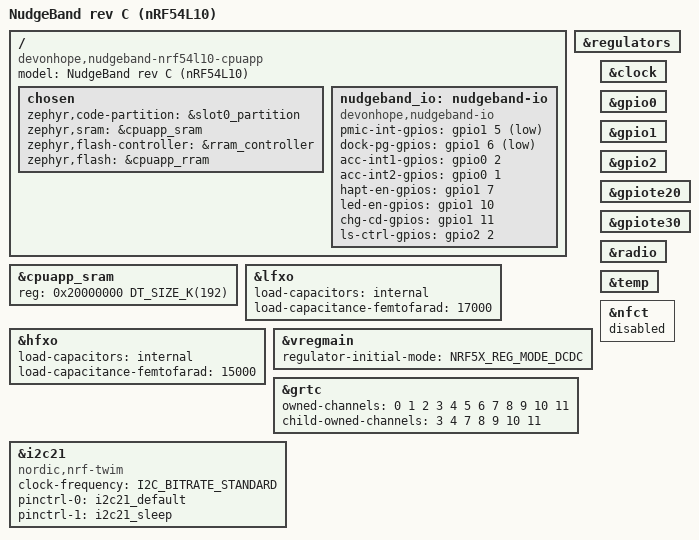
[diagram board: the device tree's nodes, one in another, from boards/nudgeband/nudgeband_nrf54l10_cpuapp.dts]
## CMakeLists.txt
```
# NudgeBand firmware (Zephyr / nRF Connect SDK application)
# SPDX-License-Identifier: MIT
cmake_minimum_required(VERSION 3.20.0)

# The NudgeBand board definition lives in this repo (boards/nudgeband).
list(APPEND BOARD_ROOT ${CMAKE_CURRENT_SOURCE_DIR})
list(APPEND DTS_ROOT ${CMAKE_CURRENT_SOURCE_DIR})

find_package(Zephyr REQUIRED HINTS $ENV{ZEPHYR_BASE})
project(nudgeband)

target_sources(app PRIVATE
	src/main.c
	src/board_io.c
	src/accel.c
	src/haptics.c
	src/led.c
	src/pmic.c
	src/ble.c
	# hardware-independent, also built by tests/host
	src/activity.c
	src/smartwake.c
	src/alarm.c
	src/protocol.c
)
```

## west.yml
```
# West manifest for building the firmware with upstream Zephyr (also what CI uses).
#   west init -l <repo checkout> --mf firmware/west.yml && west update
#   (run from the folder that holds the checkout; that folder becomes the west workspace)
# Building with nRF Connect SDK instead works too: see firmware/README.md.
manifest:
  remotes:
    - name: zephyrproject-rtos
      url-base: https://github.com/zephyrproject-rtos
  projects:
    - name: zephyr
      remote: zephyrproject-rtos
      revision: v4.2.0
      import:
        name-allowlist:
          - cmsis_6
          - hal_nordic
          - mbedtls
          - segger
```

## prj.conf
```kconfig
# NudgeBand firmware configuration
CONFIG_GPIO=y
CONFIG_I2C=y

# Logs over SEGGER RTT through the dock's SWD pins (no UART on the band)
CONFIG_LOG=y
CONFIG_USE_SEGGER_RTT=y
CONFIG_LOG_BACKEND_RTT=y
CONFIG_LOG_BACKEND_UART=n
CONFIG_CONSOLE=y
CONFIG_RTT_CONSOLE=y
CONFIG_UART_CONSOLE=n

# Bluetooth peripheral (docs/ble-protocol.md)
CONFIG_BT=y
CONFIG_BT_PERIPHERAL=y
CONFIG_BT_DEVICE_NAME="NudgeBand"
CONFIG_BT_DEVICE_NAME_DYNAMIC=y
CONFIG_BT_SMP=y
CONFIG_BT_BONDABLE=y
CONFIG_BT_MAX_PAIRED=1
CONFIG_BT_MAX_CONN=1
CONFIG_BT_GATT_DYNAMIC_DB=n
CONFIG_BT_BAS=y
CONFIG_BT_DIS=y
CONFIG_BT_DIS_MODEL="NudgeBand"
CONFIG_BT_DIS_MANUF="NudgeBand project"
CONFIG_BT_DIS_HW_REV=y
CONFIG_BT_DIS_HW_REV_STR="rev C"
CONFIG_BT_DIS_FW_REV=y
CONFIG_BT_DIS_FW_REV_STR="0.1"

# Bonds survive a reset (settings in RRAM)
CONFIG_FLASH=y
CONFIG_FLASH_MAP=y
CONFIG_ZMS=y
CONFIG_SETTINGS=y
CONFIG_BT_SETTINGS=y

CONFIG_MAIN_STACK_SIZE=2048
```

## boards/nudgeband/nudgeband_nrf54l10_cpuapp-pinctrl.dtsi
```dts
/* SPDX-License-Identifier: MIT */

&pinctrl {
	/* External pull-ups R203/R204 to the 2.0 V rail. P1.04 and P1.08 are clock-capable pins. */
	i2c21_default: i2c21_default {
		group1 {
			psels = <NRF_PSEL(TWIM_SCL, 1, 4)>,
				<NRF_PSEL(TWIM_SDA, 1, 8)>;
		};
	};

	i2c21_sleep: i2c21_sleep {
		group1 {
			psels = <NRF_PSEL(TWIM_SCL, 1, 4)>,
				<NRF_PSEL(TWIM_SDA, 1, 8)>;
			low-power-enable;
		};
	};
};
```

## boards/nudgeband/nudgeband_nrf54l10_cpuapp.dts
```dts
/*
 * NudgeBand rev C (hardware/band/rev-c/pcb). Pin map and part notes: that folder's README.md.
 *
 * SPDX-License-Identifier: MIT
 */

/dts-v1/;

#include <nordic/nrf54l10_cpuapp.dtsi>
#include "nudgeband_nrf54l10_cpuapp-pinctrl.dtsi"

/ {
	compatible = "devonhope,nudgeband-nrf54l10-cpuapp";
	model = "NudgeBand rev C (nRF54L10)";

	chosen {
		zephyr,code-partition = &slot0_partition;
		zephyr,sram = &cpuapp_sram;
		zephyr,flash-controller = &rram_controller;
		zephyr,flash = &cpuapp_rram;
	};

	/* Board signals the application drives itself (src/board_io.c). Pin map: band rev C README. */
	nudgeband_io: nudgeband-io {
		compatible = "devonhope,nudgeband-io";
		/* BQ25125 /INT and /PG are open drain with no external pull-ups: use the internal ones. */
		pmic-int-gpios = <&gpio1 5 (GPIO_ACTIVE_LOW | GPIO_PULL_UP)>;
		dock-pg-gpios = <&gpio1 6 (GPIO_ACTIVE_LOW | GPIO_PULL_UP)>; /* low while docked */
		acc-int1-gpios = <&gpio0 2 GPIO_ACTIVE_HIGH>;  /* LIS2DW12 INT1: FIFO watermark */
		acc-int2-gpios = <&gpio0 1 GPIO_ACTIVE_HIGH>;  /* LIS2DW12 INT2: double tap */
		hapt-en-gpios = <&gpio1 7 GPIO_ACTIVE_HIGH>;   /* DRV2605L EN */
		led-en-gpios = <&gpio1 10 GPIO_ACTIVE_HIGH>;   /* IS31FL3193 SDB (R211 pulls low) */
		chg-cd-gpios = <&gpio1 11 GPIO_ACTIVE_HIGH>;   /* BQ25125 /CD: high = I2C, low = Hi-Z */
		ls-ctrl-gpios = <&gpio2 2 GPIO_ACTIVE_HIGH>;   /* BQ25125 LSCTRL: LED supply */
	};

};

&cpuapp_sram {
	status = "okay";
	reg = <0x20000000 DT_SIZE_K(192)>;
	ranges = <0x0 0x20000000 DT_SIZE_K(192)>;
};

/*
 * Crystals use the chip's internal load capacitors (no external caps on the board).
 * X1 32.768 kHz CL 9 pF, X2 32 MHz CL 8 pF: same crystals' CL as the nRF54L15 DK, so its values are
 * the starting point. Check the INTCAP formula against our layout's parasitics (TODO.md, 1.3).
 */
&lfxo {
	load-capacitors = "internal";
	load-capacitance-femtofarad = <17000>;
};

&hfxo {
	load-capacitors = "internal";
	load-capacitance-femtofarad = <15000>;
};

&regulators {
	status = "okay";
};

/* L1 4.7 uH is fitted: run the main regulator as DC/DC. */
&vregmain {
	status = "okay";
	regulator-initial-mode = <NRF5X_REG_MODE_DCDC>;
};

&grtc {
	owned-channels = <0 1 2 3 4 5 6 7 8 9 10 11>;
	child-owned-channels = <3 4 7 8 9 10 11>;
	status = "okay";
};

&clock {
	status = "okay";
};

&gpio0 {
	status = "okay";
};

&gpio1 {
	status = "okay";
};

&gpio2 {
	status = "okay";
};

&gpiote20 {
	status = "okay";
};

&gpiote30 {
	status = "okay";
};

&radio {
	status = "okay";
};

&temp {
	status = "okay";
};

/* NFC pins (P1.02/P1.03) are unused. */
&nfct {
	status = "disabled";
};

&i2c21 {
	status = "okay";
	compatible = "nordic,nrf-twim";
	clock-frequency = <I2C_BITRATE_STANDARD>;
	pinctrl-0 = <&i2c21_default>;
	pinctrl-1 = <&i2c21_sleep>;
	pinctrl-names = "default", "sleep";

	/* Motion sensor: INT1 = FIFO watermark, INT2 = double tap (dismiss) */
	/*
	 * All four parts are driven by small register-level modules in src/ (fixed addresses there):
	 * LIS2DW12 0x19, DRV2605L 0x5A, IS31FL3193 0x68, BQ25125 0x6A. Zephyr's own LIS2DW12 and
	 * DRV2605 drivers can replace two of them later (TODO.md, 2.x).
	 */
};

/* Default 1 MB RRAM partitions (MCUboot slots etc.) */
#include <nordic/nrf54l10_partition.dtsi>
```

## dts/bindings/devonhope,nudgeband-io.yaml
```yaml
# SPDX-License-Identifier: MIT
description: NudgeBand board signals driven directly by the application

compatible: "devonhope,nudgeband-io"

properties:
  pmic-int-gpios:
    type: phandle-array
    required: true
    description: BQ25125 /INT
  dock-pg-gpios:
    type: phandle-array
    required: true
    description: BQ25125 /PG, active while the dock supplies VIN
  acc-int1-gpios:
    type: phandle-array
    required: true
  acc-int2-gpios:
    type: phandle-array
    required: true
  hapt-en-gpios:
    type: phandle-array
    required: true
  led-en-gpios:
    type: phandle-array
    required: true
  chg-cd-gpios:
    type: phandle-array
    required: true
  ls-ctrl-gpios:
    type: phandle-array
    required: true
```

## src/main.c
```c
/*
 * NudgeBand firmware: track movement all night, wake the wearer gently in light sleep inside the
 * window before the alarm. Status of every part: ../TODO.md.
 */
#include <zephyr/kernel.h>
#include <zephyr/logging/log.h>

#include "accel.h"
#include "activity.h"
#include "alarm.h"
#include "band.h"
#include "ble.h"
#include "board_io.h"
#include "haptics.h"
#include "led.h"
#include "pmic.h"
#include "smartwake.h"

LOG_MODULE_REGISTER(main, LOG_LEVEL_INF);

#define EPOCH_S 30

static K_MUTEX_DEFINE(lock);
static K_SEM_DEFINE(fifo_ready, 0, 1);

/* Time: UTC at the moment the phone set it, plus uptime since then. */
static uint32_t utc_at_set;
static int64_t uptime_at_set_ms;
static int16_t tz_offset_min;
static bool time_set;

static struct nb_alarm_cfg alarm_cfg;
static uint32_t next_alarm_utc;
static enum nb_state state = NB_STATE_IDLE;
static uint8_t repeats_left;
static enum nb_wake_reason last_wake_reason;
static uint32_t last_wake_utc;

static struct smartwake sw;
static struct activity_acc acc;

static void repeat_fn(struct k_work *w);
static K_WORK_DELAYABLE_DEFINE(repeat_work, repeat_fn);

uint32_t band_now_utc(void)
{
	if (!time_set) {
		return 0;
	}
	return utc_at_set + (uint32_t)((k_uptime_get() - uptime_at_set_ms) / 1000);
}

static void rearm_locked(void)
{
	struct smartwake_cfg cfg;
	uint32_t now = band_now_utc();

	next_alarm_utc = now ? alarm_next_utc(&alarm_cfg, now, tz_offset_min) : 0;
	if (!next_alarm_utc) {
		smartwake_disarm(&sw);
		state = NB_STATE_IDLE;
		return;
	}
	smartwake_default_cfg(&cfg);
	cfg.epoch_s = EPOCH_S;
	cfg.window_s = (alarm_cfg.flags & NB_ALARM_FLAG_SMARTWAKE) ? alarm_cfg.window_min * 60u : 0;
	smartwake_arm(&sw, &cfg, next_alarm_utc);
	state = NB_STATE_TRACKING;
	LOG_INF("next alarm at %u (UTC), window %u min", next_alarm_utc, cfg.window_s / 60);
}

void band_set_time(const struct nb_time *t)
{
	k_mutex_lock(&lock, K_FOREVER);
	utc_at_set = t->utc;
	uptime_at_set_ms = k_uptime_get();
	tz_offset_min = t->tz_offset_min;
	time_set = true;
	if (state == NB_STATE_IDLE || state == NB_STATE_TRACKING) {
		rearm_locked();
	}
	k_mutex_unlock(&lock);
	ble_status_changed();
}

void band_get_time(struct nb_time *t)
{
	t->utc = band_now_utc();
	t->tz_offset_min = tz_offset_min;
	t->reserved = 0;
}

void band_get_alarm(struct nb_alarm_cfg *cfg)
{
	k_mutex_lock(&lock, K_FOREVER);
	*cfg = alarm_cfg;
	k_mutex_unlock(&lock);
}

void band_set_alarm(const struct nb_alarm_cfg *cfg)
{
	k_mutex_lock(&lock, K_FOREVER);
	alarm_cfg = *cfg;
	/* TODO(TODO.md 3.5): keep the alarm in flash (settings) so a reset doesn't lose it. */
	if (state != NB_STATE_WAKING && state != NB_STATE_WAIT_REPEAT) {
		rearm_locked();
	}
	k_mutex_unlock(&lock);
	ble_status_changed();
}

void band_get_status(struct nb_status *st)
{
	k_mutex_lock(&lock, K_FOREVER);
	st->version = NB_STATUS_VERSION;
	st->state = state;
	st->battery_pct = pmic_battery_pct();
	st->flags = (pmic_docked() ? NB_FLAG_DOCKED : 0) | (time_set ? NB_FLAG_TIME_SET : 0) |
		    (next_alarm_utc ? NB_FLAG_ALARM_ARMED : 0) | (sw.n ? NB_FLAG_LOG_HAS_DATA : 0);
	/* TODO(TODO.md 2.1): NB_FLAG_CHARGING from the BQ25125 status register. */
	st->next_alarm_utc = next_alarm_utc;
	st->fw_major = FW_MAJOR;
	st->fw_minor = FW_MINOR;
	st->last_wake_reason = last_wake_reason;
	st->reserved = 0;
	st->last_wake_utc = last_wake_utc;
	st->stored_epochs = sw.n; /* RAM only for now (TODO.md 3.4) */
	k_mutex_unlock(&lock);
}

static void buzz_locked(void)
{
	(void)haptics_start(alarm_cfg.intensity, alarm_cfg.pattern, alarm_cfg.ramp_s,
			    alarm_cfg.buzz_s);
	state = NB_STATE_WAKING;
	/* After the buzz, wait repeat_min, then buzz again (until dismissed or out of repeats). */
	k_work_reschedule(&repeat_work, K_SECONDS(alarm_cfg.buzz_s));
}

static void repeat_fn(struct k_work *w)
{
	ARG_UNUSED(w);
	k_mutex_lock(&lock, K_FOREVER);
	if (state == NB_STATE_WAKING) {
		if (repeats_left == 0 || alarm_cfg.repeat_min == 0) {
			rearm_locked(); /* done: on to the next alarm */
		} else {
			repeats_left--;
			state = NB_STATE_WAIT_REPEAT;
			k_work_reschedule(&repeat_work, K_MINUTES(alarm_cfg.repeat_min));
		}
	} else if (state == NB_STATE_WAIT_REPEAT) {
		buzz_locked();
	}
	k_mutex_unlock(&lock);
	ble_status_changed();
}

static void wake_locked(enum nb_wake_reason why)
{
	last_wake_reason = why;
	last_wake_utc = band_now_utc();
	repeats_left = alarm_cfg.max_repeats;
	smartwake_disarm(&sw);
	LOG_INF("wake: reason %d", why);
	buzz_locked();
}

enum nb_cp_result band_test_buzz(uint8_t intensity_pct, uint8_t seconds)
{
	if (intensity_pct > 100 || seconds < 1 || seconds > 10) {
		return NB_CP_INVALID;
	}
	if (state == NB_STATE_WAKING) {
		return NB_CP_BUSY;
	}
	return haptics_start((uint8_t)(intensity_pct * 255u / 100u), 0, 1, seconds) ? NB_CP_BUSY
										     : NB_CP_OK;
}

void band_stop_buzz(void)
{
	haptics_stop();
}

void band_dismiss(void)
{
	k_mutex_lock(&lock, K_FOREVER);
	haptics_stop();
	k_work_cancel_delayable(&repeat_work);
	if (state == NB_STATE_WAKING || state == NB_STATE_WAIT_REPEAT ||
	    state == NB_STATE_IN_WINDOW) {
		/* TODO(TODO.md 3.3): dismissing during the window should skip today's alarm only. */
		rearm_locked();
	}
	k_mutex_unlock(&lock);
	ble_status_changed();
}

void band_identify(void)
{
	/* TODO(TODO.md 2.4): blink twice from a work item instead of a fixed on-time. */
	(void)led_set(0, 0, 64);
	k_msleep(300);
	(void)led_set(0, 0, 0);
}

/* Called once per epoch with that epoch's activity. */
static void end_of_epoch(uint16_t activity)
{
	enum smartwake_result r;
	uint32_t now;
	bool changed = false;

	k_mutex_lock(&lock, K_FOREVER);
	now = band_now_utc();
	r = now ? smartwake_feed(&sw, now, activity) : SMARTWAKE_NONE;
	if (state == NB_STATE_TRACKING && sw.armed && now + sw.cfg.window_s >= sw.alarm_s) {
		state = NB_STATE_IN_WINDOW;
		changed = true;
	}
	if (r == SMARTWAKE_LIGHT_SLEEP) {
		wake_locked(NB_WAKE_LIGHT_SLEEP);
		changed = true;
	} else if (r == SMARTWAKE_DEADLINE) {
		wake_locked((alarm_cfg.flags & NB_ALARM_FLAG_SMARTWAKE) ? NB_WAKE_DEADLINE
									 : NB_WAKE_EXACT);
		changed = true;
	}
	k_mutex_unlock(&lock);
	if (changed) {
		ble_status_changed();
	}
}

static struct gpio_callback acc_cb;

static void acc_int1_isr(const struct device *dev, struct gpio_callback *cb, uint32_t pins)
{
	k_sem_give(&fifo_ready);
}

int main(void)
{
	static struct accel_sample batch[32];
	int64_t epoch_end_ms;
	int err;

	LOG_INF("NudgeBand firmware %d.%d", FW_MAJOR, FW_MINOR);

	nb_alarm_cfg_default(&alarm_cfg);
	err = board_io_init();
	if (err) {
		LOG_ERR("board_io_init failed (%d)", err);
		return 0;
	}
	(void)pmic_init();
	(void)led_init();
	(void)haptics_init();
	err = accel_init();
	(void)ble_init();

	if (err == 0) {
		gpio_pin_interrupt_configure_dt(&io_acc_int1, GPIO_INT_EDGE_TO_ACTIVE);
		gpio_init_callback(&acc_cb, acc_int1_isr, BIT(io_acc_int1.pin));
		gpio_add_callback_dt(&io_acc_int1, &acc_cb);
		activity_reset(&acc);
		(void)accel_start();
	}

	epoch_end_ms = k_uptime_get() + EPOCH_S * 1000;
	for (;;) {
		/* The FIFO interrupt normally wakes us every 2 s; the timeout covers a missed one. */
		(void)k_sem_take(&fifo_ready, K_SECONDS(3));

		int n = accel_read_fifo(batch, ARRAY_SIZE(batch));

		if (n > 0) {
			activity_add(&acc, batch, (uint32_t)n);
		}
		/* TODO(TODO.md 3.1): mark epochs as "no data" (0xFFFF) while docked or off the wrist. */
		while (k_uptime_get() >= epoch_end_ms) {
			end_of_epoch(activity_end_epoch(&acc));
			epoch_end_ms += EPOCH_S * 1000;
		}
	}
	return 0;
}
```

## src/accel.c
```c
/*
 * LIS2DW12 register-level driver. Register map: ST DS12086.
 * Low-power mode 1 (12-bit), 12.5 Hz, +/-2 g, FIFO in continuous mode with a watermark on INT1.
 */
#include "accel.h"

#include <zephyr/logging/log.h>
#include <zephyr/sys/byteorder.h>

#include "board_io.h"

LOG_MODULE_REGISTER(accel, LOG_LEVEL_INF);

#define ADDR 0x19

#define REG_WHO_AM_I    0x0F
#define WHO_AM_I_VALUE  0x44
#define REG_CTRL1       0x20
#define REG_CTRL2       0x21
#define REG_CTRL4_INT1  0x23
#define REG_CTRL6       0x25
#define REG_OUT_X_L     0x28
#define REG_FIFO_CTRL   0x2E
#define REG_FIFO_SAMPLES 0x2F

#define CTRL1_ODR_12HZ5    (0x2 << 4)
#define CTRL1_ODR_OFF      (0x0 << 4)
#define CTRL1_LP_MODE1     0x00 /* MODE = low power, LP_MODE = 1 (12-bit) */
#define CTRL2_SOFT_RESET   BIT(6)
#define CTRL2_BDU          BIT(3)
#define CTRL2_IF_ADD_INC   BIT(2)
#define CTRL4_INT1_FTH     BIT(1)
#define CTRL6_FS_2G        (0x0 << 4)
#define FIFO_MODE_BYPASS   (0x0 << 5)
#define FIFO_MODE_CONT     (0x6 << 5)
#define FIFO_SAMPLES_MASK  0x3F

static int wr(uint8_t reg, uint8_t val)
{
	return i2c_reg_write_byte(i2c_bus, ADDR, reg, val);
}

int accel_init(void)
{
	uint8_t id;
	int err = i2c_reg_read_byte(i2c_bus, ADDR, REG_WHO_AM_I, &id);

	if (err) {
		LOG_ERR("no answer at 0x%02x (%d)", ADDR, err);
		return err;
	}
	if (id != WHO_AM_I_VALUE) {
		LOG_ERR("WHO_AM_I 0x%02x, expected 0x%02x", id, WHO_AM_I_VALUE);
		return -ENODEV;
	}
	err = wr(REG_CTRL2, CTRL2_SOFT_RESET);
	k_msleep(5);
	err = err ?: wr(REG_CTRL2, CTRL2_BDU | CTRL2_IF_ADD_INC);
	err = err ?: wr(REG_CTRL6, CTRL6_FS_2G);
	err = err ?: wr(REG_CTRL4_INT1, CTRL4_INT1_FTH);
	return err;
}

int accel_start(void)
{
	int err = wr(REG_FIFO_CTRL, FIFO_MODE_BYPASS); /* clears the FIFO */

	err = err ?: wr(REG_FIFO_CTRL, FIFO_MODE_CONT | ACCEL_FIFO_WTM);
	err = err ?: wr(REG_CTRL1, CTRL1_ODR_12HZ5 | CTRL1_LP_MODE1);
	return err;
}

int accel_stop(void)
{
	return wr(REG_CTRL1, CTRL1_ODR_OFF);
}

int accel_read_fifo(struct accel_sample *out, int max)
{
	uint8_t level;
	int n;
	int err = i2c_reg_read_byte(i2c_bus, ADDR, REG_FIFO_SAMPLES, &level);

	if (err) {
		return err;
	}
	n = MIN((int)(level & FIFO_SAMPLES_MASK), max);
	for (int i = 0; i < n; i++) {
		uint8_t raw[6];

		err = i2c_burst_read(i2c_bus, ADDR, REG_OUT_X_L, raw, sizeof(raw));
		if (err) {
			return err;
		}
		/* 12-bit, left-aligned; at +/-2 g one LSB of the 12-bit value is 0.976 mg */
		out[i].x = (int16_t)(((int32_t)(int16_t)sys_get_le16(&raw[0]) >> 4) * 976 / 1000);
		out[i].y = (int16_t)(((int32_t)(int16_t)sys_get_le16(&raw[2]) >> 4) * 976 / 1000);
		out[i].z = (int16_t)(((int32_t)(int16_t)sys_get_le16(&raw[4]) >> 4) * 976 / 1000);
	}
	return n;
}
```

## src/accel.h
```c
/* LIS2DW12 motion sensor: low-power sampling into its FIFO, read in batches. */
#ifndef NUDGEBAND_ACCEL_H
#define NUDGEBAND_ACCEL_H

#include <stdint.h>

#include "activity.h"

#define ACCEL_ODR_HZ   12.5
#define ACCEL_FIFO_WTM 25 /* samples per batch: one wake every 2 s */

int accel_init(void);

/* Start sampling; INT1 fires each time ACCEL_FIFO_WTM samples are waiting. */
int accel_start(void);
int accel_stop(void);

/* Read every sample in the FIFO (up to max), in mg. Returns the count or a negative error. */
int accel_read_fifo(struct accel_sample *out, int max);

#endif
```

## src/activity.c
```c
#include "activity.h"

static uint32_t absdiff(int16_t a, int16_t b)
{
	int32_t d = (int32_t)a - (int32_t)b;

	return (uint32_t)(d < 0 ? -d : d);
}

void activity_reset(struct activity_acc *acc)
{
	acc->have_prev = false;
	acc->sum = 0;
}

void activity_add(struct activity_acc *acc, const struct accel_sample *s, uint32_t n)
{
	for (uint32_t i = 0; i < n; i++) {
		if (acc->have_prev) {
			uint32_t d = absdiff(s[i].x, acc->prev.x) + absdiff(s[i].y, acc->prev.y) +
				     absdiff(s[i].z, acc->prev.z);

			if (d > ACTIVITY_DEADBAND_MG) {
				acc->sum += d - ACTIVITY_DEADBAND_MG;
				if (acc->sum > ACTIVITY_MAX) {
					acc->sum = ACTIVITY_MAX;
				}
			}
		}
		acc->prev = s[i];
		acc->have_prev = true;
	}
}

uint16_t activity_end_epoch(struct activity_acc *acc)
{
	uint16_t a = (uint16_t)acc->sum;

	acc->sum = 0;
	return a;
}
```

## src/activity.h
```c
/*
 * Movement measure for one sleep epoch (pure C, no Zephyr; unit-tested on the host).
 *
 * Each accelerometer sample is compared with the one before it. The change on x, y and z is
 * added up (|dx| + |dy| + |dz|, in mg), a small deadband is taken off to ignore sensor noise,
 * and what is left is summed over the epoch. Gravity cancels out because only changes count,
 * so the band's orientation on the wrist does not matter.
 */
#ifndef NUDGEBAND_ACTIVITY_H
#define NUDGEBAND_ACTIVITY_H

#include <stdbool.h>
#include <stdint.h>

/* Samples whose summed change is at or below this (mg) count as noise. */
#define ACTIVITY_DEADBAND_MG 20
/* Largest activity value; 0xFFFF means "no data" in the sleep log (docs/ble-protocol.md). */
#define ACTIVITY_MAX   0xFFFEu
#define ACTIVITY_NONE  0xFFFFu

struct accel_sample {
	int16_t x; /* mg */
	int16_t y;
	int16_t z;
};

struct activity_acc {
	struct accel_sample prev;
	bool have_prev;
	uint32_t sum; /* mg above the deadband, this epoch */
};

void activity_reset(struct activity_acc *acc);

/* Add samples (may be called many times per epoch, e.g. once per FIFO read). */
void activity_add(struct activity_acc *acc, const struct accel_sample *s, uint32_t n);

/*
 * Finish the epoch: returns its activity (saturated to ACTIVITY_MAX) and clears the sum.
 * The last sample is kept so the next epoch's first change is measured too.
 */
uint16_t activity_end_epoch(struct activity_acc *acc);

#endif
```

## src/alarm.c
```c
#include "alarm.h"

uint32_t alarm_next_utc(const struct nb_alarm_cfg *cfg, uint32_t now_utc, int16_t tz_offset_min)
{
	int64_t off = (int64_t)tz_offset_min * 60;
	int64_t local_now = (int64_t)now_utc + off;
	int64_t day = local_now / 86400;
	int64_t tod = (int64_t)cfg->hour * 3600 + (int64_t)cfg->minute * 60;

	if (!(cfg->flags & NB_ALARM_FLAG_ENABLED)) {
		return 0;
	}
	for (int64_t d = day; d <= day + 7; d++) {
		int64_t local = d * 86400 + tod;

		if (local <= local_now) {
			continue;
		}
		if (cfg->days != 0 && !(cfg->days & (1u << alarm_weekday((uint32_t)d)))) {
			continue;
		}
		return (uint32_t)(local - off);
	}
	return 0; /* not reached: some day in the next week always matches */
}
```

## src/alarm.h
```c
/*
 * When is the next alarm? (pure C, unit-tested on the host)
 *
 * The band keeps UTC and the UTC offset the phone last wrote. Daylight-saving changes are picked up
 * the next time the phone connects (TODO.md, 3.2).
 */
#ifndef NUDGEBAND_ALARM_H
#define NUDGEBAND_ALARM_H

#include <stdint.h>

#include "protocol.h"

/*
 * Next alarm time (UTC seconds) strictly after now_utc, or 0 if the alarm is disabled.
 * The smart-wake window ends at this time and starts window_min before it.
 */
uint32_t alarm_next_utc(const struct nb_alarm_cfg *cfg, uint32_t now_utc, int16_t tz_offset_min);

/* Day of week of a local-time day number (days since 1970-01-01), 0 = Monday. */
static inline uint8_t alarm_weekday(uint32_t local_day)
{
	return (uint8_t)((local_day + 3u) % 7u); /* 1970-01-01 was a Thursday */
}

#endif
```

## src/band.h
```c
/* The band's shared state and the actions the Bluetooth service can ask for (main.c). */
#ifndef NUDGEBAND_BAND_H
#define NUDGEBAND_BAND_H

#include <stdbool.h>
#include <stdint.h>

#include "protocol.h"

#define FW_MAJOR 0
#define FW_MINOR 1

/* UTC now, or 0 if the phone has not set the time since power-up. */
uint32_t band_now_utc(void);

void band_set_time(const struct nb_time *t);
void band_get_time(struct nb_time *t);

void band_get_alarm(struct nb_alarm_cfg *cfg);
void band_set_alarm(const struct nb_alarm_cfg *cfg); /* already validated */

void band_get_status(struct nb_status *st);

enum nb_cp_result band_test_buzz(uint8_t intensity_pct, uint8_t seconds);
void band_stop_buzz(void);
void band_dismiss(void);
void band_identify(void);

#endif
```

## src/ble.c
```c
/*
 * GATT side of docs/ble-protocol.md. Standard Battery and Device Information services come from
 * Zephyr (CONFIG_BT_BAS, CONFIG_BT_DIS); MCUmgr SMP for updates over the air is TODO.md 4.6.
 */
#include "ble.h"

#include <string.h>

#include <zephyr/bluetooth/bluetooth.h>
#include <zephyr/bluetooth/conn.h>
#include <zephyr/bluetooth/gatt.h>
#include <zephyr/bluetooth/uuid.h>
#include <zephyr/logging/log.h>
#include <zephyr/settings/settings.h>

#include "band.h"
#include "protocol.h"

LOG_MODULE_REGISTER(ble, LOG_LEVEL_INF);

#define NB_UUID(short16) BT_UUID_128_ENCODE(NB_UUID_BASE_W32 | (short16), 0xa414, 0x4c37, 0x89d9, \
					    0x4dcc3036748eULL)

static const struct bt_uuid_128 uuid_svc = BT_UUID_INIT_128(NB_UUID(NB_UUID_SERVICE));
static const struct bt_uuid_128 uuid_time = BT_UUID_INIT_128(NB_UUID(NB_UUID_TIME));
static const struct bt_uuid_128 uuid_alarm = BT_UUID_INIT_128(NB_UUID(NB_UUID_ALARM));
static const struct bt_uuid_128 uuid_status = BT_UUID_INIT_128(NB_UUID(NB_UUID_STATUS));
static const struct bt_uuid_128 uuid_control = BT_UUID_INIT_128(NB_UUID(NB_UUID_CONTROL));
static const struct bt_uuid_128 uuid_log = BT_UUID_INIT_128(NB_UUID(NB_UUID_LOG));

static bool status_notify;
static bool control_indicate;

/* --- Time --- */

static ssize_t read_time(struct bt_conn *conn, const struct bt_gatt_attr *attr, void *buf,
			 uint16_t len, uint16_t offset)
{
	struct nb_time t;

	band_get_time(&t);
	return bt_gatt_attr_read(conn, attr, buf, len, offset, &t, sizeof(t));
}

static ssize_t write_time(struct bt_conn *conn, const struct bt_gatt_attr *attr, const void *buf,
			  uint16_t len, uint16_t offset, uint8_t flags)
{
	struct nb_time t;

	if (offset != 0 || len != sizeof(t)) {
		return BT_GATT_ERR(BT_ATT_ERR_INVALID_ATTRIBUTE_LEN);
	}
	memcpy(&t, buf, sizeof(t));
	band_set_time(&t);
	return len;
}

/* --- Alarm config --- */

static ssize_t read_alarm(struct bt_conn *conn, const struct bt_gatt_attr *attr, void *buf,
			  uint16_t len, uint16_t offset)
{
	struct nb_alarm_cfg c;

	band_get_alarm(&c);
	return bt_gatt_attr_read(conn, attr, buf, len, offset, &c, sizeof(c));
}

static ssize_t write_alarm(struct bt_conn *conn, const struct bt_gatt_attr *attr, const void *buf,
			   uint16_t len, uint16_t offset, uint8_t flags)
{
	struct nb_alarm_cfg c;

	if (offset != 0 || len != sizeof(c)) {
		return BT_GATT_ERR(BT_ATT_ERR_INVALID_ATTRIBUTE_LEN);
	}
	memcpy(&c, buf, sizeof(c));
	if (!nb_alarm_cfg_valid(&c)) {
		return BT_GATT_ERR(BT_ATT_ERR_VALUE_NOT_ALLOWED);
	}
	band_set_alarm(&c);
	return len;
}

/* --- Status --- */

static ssize_t read_status(struct bt_conn *conn, const struct bt_gatt_attr *attr, void *buf,
			   uint16_t len, uint16_t offset)
{
	struct nb_status st;

	band_get_status(&st);
	return bt_gatt_attr_read(conn, attr, buf, len, offset, &st, sizeof(st));
}

static void status_ccc(const struct bt_gatt_attr *attr, uint16_t value)
{
	status_notify = (value == BT_GATT_CCC_NOTIFY);
}

/* --- Control point --- */

static void control_ccc(const struct bt_gatt_attr *attr, uint16_t value)
{
	control_indicate = (value == BT_GATT_CCC_INDICATE);
}

static ssize_t write_control(struct bt_conn *conn, const struct bt_gatt_attr *attr,
			     const void *buf, uint16_t len, uint16_t offset, uint8_t flags);

static void log_ccc(const struct bt_gatt_attr *attr, uint16_t value)
{
	ARG_UNUSED(attr);
	ARG_UNUSED(value);
}

BT_GATT_SERVICE_DEFINE(nb_svc,
	BT_GATT_PRIMARY_SERVICE(&uuid_svc),
	BT_GATT_CHARACTERISTIC(&uuid_time.uuid, BT_GATT_CHRC_READ | BT_GATT_CHRC_WRITE,
			       BT_GATT_PERM_READ | BT_GATT_PERM_WRITE_ENCRYPT, read_time,
			       write_time, NULL),
	BT_GATT_CHARACTERISTIC(&uuid_alarm.uuid, BT_GATT_CHRC_READ | BT_GATT_CHRC_WRITE,
			       BT_GATT_PERM_READ | BT_GATT_PERM_WRITE_ENCRYPT, read_alarm,
			       write_alarm, NULL),
	BT_GATT_CHARACTERISTIC(&uuid_status.uuid, BT_GATT_CHRC_READ | BT_GATT_CHRC_NOTIFY,
			       BT_GATT_PERM_READ, read_status, NULL, NULL),
	BT_GATT_CCC(status_ccc, BT_GATT_PERM_READ | BT_GATT_PERM_WRITE),
	BT_GATT_CHARACTERISTIC(&uuid_control.uuid, BT_GATT_CHRC_WRITE | BT_GATT_CHRC_INDICATE,
			       BT_GATT_PERM_WRITE_ENCRYPT, NULL, write_control, NULL),
	BT_GATT_CCC(control_ccc, BT_GATT_PERM_READ | BT_GATT_PERM_WRITE_ENCRYPT),
	BT_GATT_CHARACTERISTIC(&uuid_log.uuid, BT_GATT_CHRC_NOTIFY, BT_GATT_PERM_NONE, NULL, NULL,
			       NULL),
	BT_GATT_CCC(log_ccc, BT_GATT_PERM_READ | BT_GATT_PERM_WRITE_ENCRYPT),
);

/* Attribute indexes in nb_svc.attrs (value attributes) */
#define ATTR_STATUS  6
#define ATTR_CONTROL 9

static struct bt_gatt_indicate_params ind_params;
static uint8_t ind_buf[3];

static void respond(struct bt_conn *conn, uint8_t opcode, enum nb_cp_result result)
{
	if (!control_indicate) {
		return;
	}
	ind_buf[0] = NB_CP_RESPONSE;
	ind_buf[1] = opcode;
	ind_buf[2] = result;
	memset(&ind_params, 0, sizeof(ind_params));
	ind_params.attr = &nb_svc.attrs[ATTR_CONTROL];
	ind_params.data = ind_buf;
	ind_params.len = sizeof(ind_buf);
	(void)bt_gatt_indicate(conn, &ind_params);
}

static ssize_t write_control(struct bt_conn *conn, const struct bt_gatt_attr *attr,
			     const void *buf, uint16_t len, uint16_t offset, uint8_t flags)
{
	const uint8_t *p = buf;
	enum nb_cp_result r = NB_CP_OK;

	if (offset != 0 || len < 1) {
		return BT_GATT_ERR(BT_ATT_ERR_INVALID_ATTRIBUTE_LEN);
	}
	switch (p[0]) {
	case NB_CP_TEST_BUZZ:
		r = (len == 3) ? band_test_buzz(p[1], p[2]) : NB_CP_INVALID;
		break;
	case NB_CP_STOP_BUZZ:
		band_stop_buzz();
		break;
	case NB_CP_DISMISS:
		band_dismiss();
		break;
	case NB_CP_IDENTIFY:
		band_identify();
		break;
	case NB_CP_LOG_READ:  /* TODO.md 4.4 */
	case NB_CP_LOG_CLEAR: /* TODO.md 4.4 */
	default:
		r = NB_CP_UNSUPPORTED;
		break;
	}
	respond(conn, p[0], r);
	return len;
}

void ble_status_changed(void)
{
	struct nb_status st;

	if (!status_notify) {
		return;
	}
	band_get_status(&st);
	(void)bt_gatt_notify(NULL, &nb_svc.attrs[ATTR_STATUS], &st, sizeof(st));
}

/* --- Advertising and connections --- */

static const struct bt_data ad[] = {
	BT_DATA_BYTES(BT_DATA_FLAGS, (BT_LE_AD_GENERAL | BT_LE_AD_NO_BREDR)),
	BT_DATA_BYTES(BT_DATA_UUID128_ALL, NB_UUID(NB_UUID_SERVICE)),
};

static char name[sizeof("NudgeBand-XXXX")];
static struct bt_data sd[1];

/* About 1 s between advertisements (TODO.md 4.1: tune for battery, faster after undocking). */
#define ADV_PARAM BT_LE_ADV_PARAM(BT_LE_ADV_OPT_CONN, 1600, 1760, NULL)

static void adv_start(void)
{
	int err = bt_le_adv_start(ADV_PARAM, ad, ARRAY_SIZE(ad), sd, ARRAY_SIZE(sd));

	if (err && err != -EALREADY) {
		LOG_ERR("advertising failed (%d)", err);
	}
}

static void connected(struct bt_conn *conn, uint8_t err)
{
	if (err) {
		return;
	}
	LOG_INF("connected");
	/* Ask for encryption straight away; Just Works pairing on the first connection. */
	(void)bt_conn_set_security(conn, BT_SECURITY_L2);
}

static void disconnected(struct bt_conn *conn, uint8_t reason)
{
	LOG_INF("disconnected (0x%02x)", reason);
}

static void recycled(void)
{
	adv_start();
}

BT_CONN_CB_DEFINE(conn_cb) = {
	.connected = connected,
	.disconnected = disconnected,
	.recycled = recycled,
};

int ble_init(void)
{
	bt_addr_le_t addr;
	size_t count = 1;
	int err = bt_enable(NULL);

	if (err) {
		LOG_ERR("bt_enable failed (%d)", err);
		return err;
	}
	if (IS_ENABLED(CONFIG_BT_SETTINGS)) {
		settings_load();
	}
	bt_id_get(&addr, &count);
	snprintk(name, sizeof(name), "NudgeBand-%02X%02X", addr.a.val[1], addr.a.val[0]);
	(void)bt_set_name(name);
	sd[0].type = BT_DATA_NAME_COMPLETE;
	sd[0].data_len = strlen(name);
	sd[0].data = (const uint8_t *)name;
	adv_start();
	LOG_INF("advertising as %s", name);
	return 0;
}
```

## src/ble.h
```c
/* NudgeBand Bluetooth service (docs/ble-protocol.md). */
#ifndef NUDGEBAND_BLE_H
#define NUDGEBAND_BLE_H

int ble_init(void);

/* Tell a subscribed phone that Status changed. */
void ble_status_changed(void);

#endif
```

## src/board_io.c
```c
#include "board_io.h"

#include <zephyr/logging/log.h>

LOG_MODULE_REGISTER(board_io, LOG_LEVEL_INF);

#define IO DT_NODELABEL(nudgeband_io)

const struct gpio_dt_spec io_pmic_int = GPIO_DT_SPEC_GET(IO, pmic_int_gpios);
const struct gpio_dt_spec io_dock_pg = GPIO_DT_SPEC_GET(IO, dock_pg_gpios);
const struct gpio_dt_spec io_acc_int1 = GPIO_DT_SPEC_GET(IO, acc_int1_gpios);
const struct gpio_dt_spec io_acc_int2 = GPIO_DT_SPEC_GET(IO, acc_int2_gpios);
const struct gpio_dt_spec io_hapt_en = GPIO_DT_SPEC_GET(IO, hapt_en_gpios);
const struct gpio_dt_spec io_led_en = GPIO_DT_SPEC_GET(IO, led_en_gpios);
const struct gpio_dt_spec io_chg_cd = GPIO_DT_SPEC_GET(IO, chg_cd_gpios);
const struct gpio_dt_spec io_ls_ctrl = GPIO_DT_SPEC_GET(IO, ls_ctrl_gpios);

const struct device *const i2c_bus = DEVICE_DT_GET(DT_NODELABEL(i2c21));

int board_io_init(void)
{
	const struct gpio_dt_spec *in[] = {&io_pmic_int, &io_dock_pg, &io_acc_int1, &io_acc_int2};
	/* All outputs start low: motor driver off, LED driver in shutdown, charger Hi-Z (/CD low,
	 * which also lets it charge on the dock), LED supply off. */
	const struct gpio_dt_spec *out[] = {&io_hapt_en, &io_led_en, &io_chg_cd, &io_ls_ctrl};
	int err;

	if (!device_is_ready(i2c_bus)) {
		LOG_ERR("I2C bus not ready");
		return -ENODEV;
	}
	for (size_t i = 0; i < ARRAY_SIZE(in); i++) {
		err = gpio_pin_configure_dt(in[i], GPIO_INPUT);
		if (err) {
			return err;
		}
	}
	for (size_t i = 0; i < ARRAY_SIZE(out); i++) {
		err = gpio_pin_configure_dt(out[i], GPIO_OUTPUT_INACTIVE);
		if (err) {
			return err;
		}
	}
	return 0;
}
```

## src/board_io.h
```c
/* Board GPIOs from the devicetree node "nudgeband-io" (boards/nudgeband). */
#ifndef NUDGEBAND_BOARD_IO_H
#define NUDGEBAND_BOARD_IO_H

#include <zephyr/device.h>
#include <zephyr/drivers/gpio.h>
#include <zephyr/drivers/i2c.h>

extern const struct gpio_dt_spec io_pmic_int;
extern const struct gpio_dt_spec io_dock_pg;
extern const struct gpio_dt_spec io_acc_int1;
extern const struct gpio_dt_spec io_acc_int2;
extern const struct gpio_dt_spec io_hapt_en;
extern const struct gpio_dt_spec io_led_en;
extern const struct gpio_dt_spec io_chg_cd;
extern const struct gpio_dt_spec io_ls_ctrl;

/* The one I2C bus: LIS2DW12 0x19, DRV2605L 0x5A, IS31FL3193 0x68, BQ25125 0x6A. */
extern const struct device *const i2c_bus;

int board_io_init(void);

#endif
```

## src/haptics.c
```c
/*
 * DRV2605L register-level driver (TI SLOS854). The motor is driven in real-time playback (RTP)
 * mode so the firmware can ramp the strength itself. EN is held low between buzzes (shutdown).
 */
#include "haptics.h"

#include <zephyr/kernel.h>
#include <zephyr/logging/log.h>

#include "board_io.h"

LOG_MODULE_REGISTER(haptics, LOG_LEVEL_INF);

#define ADDR 0x5A

#define REG_STATUS    0x00
#define REG_MODE      0x01
#define REG_RTP       0x02
#define REG_LIBRARY   0x03
#define REG_FEEDBACK  0x1A
#define REG_CONTROL3  0x1D

#define MODE_RTP          0x05
#define MODE_STANDBY      BIT(6)
#define LIBRARY_LRA       0x06
#define FEEDBACK_LRA      BIT(7)
#define CONTROL3_RTP_UNSIGNED BIT(3)

#define STEP_MS 50

static struct k_work_delayable step_work;
static uint32_t elapsed_ms;
static uint32_t ramp_ms;
static uint32_t total_ms;
static uint8_t target;
static uint8_t pat;
static bool running;

static int wr(uint8_t reg, uint8_t val)
{
	return i2c_reg_write_byte(i2c_bus, ADDR, reg, val);
}

/* Strength at this moment of the pattern, 0-255. */
static uint8_t level_now(void)
{
	uint32_t lvl = target;

	if (elapsed_ms < ramp_ms) {
		lvl = lvl * elapsed_ms / ramp_ms;
	}
	switch (pat) {
	case 1: /* slow pulses: 1 s on, 1 s off */
		return (elapsed_ms / 1000) % 2 ? 0 : (uint8_t)lvl;
	case 2: /* heartbeat: two short beats every 1.2 s */
	{
		uint32_t t = elapsed_ms % 1200;

		return (t < 150 || (t >= 300 && t < 450)) ? (uint8_t)lvl : 0;
	}
	default:
		return (uint8_t)lvl;
	}
}

static void power_down(void)
{
	(void)wr(REG_RTP, 0);
	(void)wr(REG_MODE, MODE_STANDBY);
	gpio_pin_set_dt(&io_hapt_en, 0);
	running = false;
}

static void step(struct k_work *work)
{
	ARG_UNUSED(work);
	if (!running) {
		return;
	}
	if (elapsed_ms >= total_ms) {
		power_down();
		return;
	}
	(void)wr(REG_RTP, level_now());
	elapsed_ms += STEP_MS;
	k_work_reschedule(&step_work, K_MSEC(STEP_MS));
}

int haptics_init(void)
{
	uint8_t st;
	int err;

	k_work_init_delayable(&step_work, step);

	gpio_pin_set_dt(&io_hapt_en, 1);
	k_msleep(1);
	err = i2c_reg_read_byte(i2c_bus, ADDR, REG_STATUS, &st);
	if (err) {
		LOG_ERR("no answer at 0x%02x (%d)", ADDR, err);
		gpio_pin_set_dt(&io_hapt_en, 0);
		return err;
	}
	LOG_INF("DRV2605L status 0x%02x (device id %u)", st, st >> 5);
	/*
	 * TODO(TODO.md 2.3): auto-calibrate for the VG0832012 (rated voltage, overdrive clamp,
	 * drive time from its resonant frequency) and store the result; until then the chip's LRA
	 * defaults apply.
	 */
	power_down();
	return 0;
}

int haptics_start(uint8_t intensity, uint8_t pattern, uint8_t ramp_s, uint8_t buzz_s)
{
	int err;

	gpio_pin_set_dt(&io_hapt_en, 1);
	k_msleep(1);
	err = wr(REG_FEEDBACK, FEEDBACK_LRA);
	err = err ?: wr(REG_LIBRARY, LIBRARY_LRA);
	err = err ?: wr(REG_CONTROL3, CONTROL3_RTP_UNSIGNED);
	err = err ?: wr(REG_RTP, 0);
	err = err ?: wr(REG_MODE, MODE_RTP);
	if (err) {
		gpio_pin_set_dt(&io_hapt_en, 0);
		return err;
	}
	target = intensity;
	pat = pattern;
	ramp_ms = (uint32_t)ramp_s * 1000;
	total_ms = (uint32_t)buzz_s * 1000;
	elapsed_ms = 0;
	running = true;
	k_work_reschedule(&step_work, K_NO_WAIT);
	return 0;
}

void haptics_stop(void)
{
	running = false;
	k_work_cancel_delayable(&step_work);
	power_down();
}

bool haptics_busy(void)
{
	return running;
}
```
